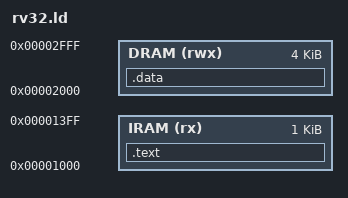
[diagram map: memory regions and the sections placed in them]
OUTPUT_ARCH("riscv")
OUTPUT_FORMAT("elf32-littleriscv")

MEMORY
{
	/* VM Addresses */
	IRAM (rx)	: ORIGIN = 0x1000, LENGTH = 1k
	DRAM (rwx)	: ORIGIN = 0x2000, LENGTH = 4k
}

ENTRY(_start)
SECTIONS
{
    .text : {
        *(.text)
    } > IRAM
    .data : {
        *(.data)
    } > DRAM

    PROVIDE(stack_top = 0x2000 + 4k);
    _end = .;
}
